# ATtiny841 device description
Architecture: AVR8; Family: tinyAVR
Registers are 8-bit, access not given, no defined reset value unless marked. A register's access mark holds for its fields unless they carry their own. Offsets are from the block's base; [hi:lo] are bit positions.

## PORTA — I/O Port
Instances: PORTA 0x00
0x39 PINA — Port A Input Pins
0x3A DDRA — Data Direction Register, Port A
0x3B PORTA — Port A Data Register
0x63 PUEA — Pull-up Enable Control Register
0x64 PORTCR — Port Control Register
  [0] BBMA — Break-Before-Make Mode Enable
0x6A PHDE — Port High Drive Enable Register
  [1:0] PHDEA — PortA High Drive Enable

## USART1 — USART
Instances: USART1 0x00
0x90 UDR1 — USART I/O Data Register
0x91 UBRR1 16-bit bits used 11:0 — USART Baud Rate Register Bytes
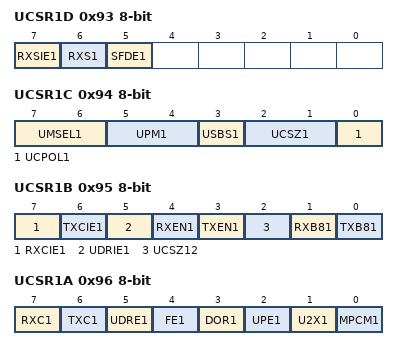
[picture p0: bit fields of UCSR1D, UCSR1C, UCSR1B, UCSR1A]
0x93 UCSR1D — USART Control and Status Register D
  [7] RXSIE1 — USART RX Start Interrupt Enable
  [6] RXS1 — USART RX Start Flag
  [5] SFDE1 — USART RX Start Frame Detection Enable
0x94 UCSR1C — USART Control and Status Register C
  [7:6] UMSEL1 — USART Mode Select
    0=Asynchronous USART; 1=Synchronous USART; 3=Master SPI
  [5:4] UPM1 — Parity Mode Bits
    0=Disabled; 2=Enabled, Even Parity; 3=Enabled, Odd Parity
  [3] USBS1 — Stop Bit Select
    0=1-bit; 1=2-bit
  [2:1] UCSZ1 — Character Size
  [0] UCPOL1 — Clock Polarity
0x95 UCSR1B — USART Control and Status Register B
  [7] RXCIE1 — RX Complete Interrupt Enable
  [6] TXCIE1 — TX Complete Interrupt Enable
  [5] UDRIE1 — USART Data register Empty Interrupt Enable
  [4] RXEN1 — Receiver Enable
  [3] TXEN1 — Transmitter Enable
  [2] UCSZ12 — Character Size
  [1] RXB81 — Receive Data Bit 8
  [0] TXB81 — Transmit Data Bit 8
0x96 UCSR1A — USART Control and Status Register A
  [7] RXC1 — USART Receive Complete
  [6] TXC1 — USART Transmitt Complete
  [5] UDRE1 — USART Data Register Empty
  [4] FE1 — Framing Error
  [3] DOR1 — Data overRun
  [2] UPE1 — Parity Error
  [1] U2X1 — Double the USART transmission speed
  [0] MPCM1 — Multi-processor Communication Mode

## USART0 — USART
Instances: USART0 0x00
0x65 REMAP — Remap Port Pins
  [0] U0MAP — USART0 Pin Mapping
0x80 UDR0 — USART I/O Data Register
0x81 UBRR0 16-bit bits used 11:0 — USART Baud Rate Register Bytes
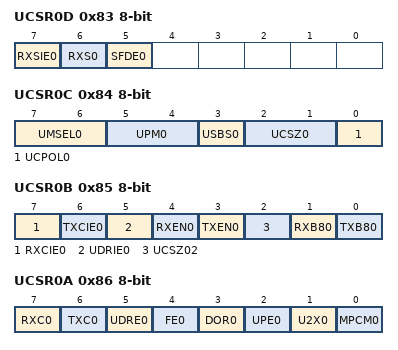
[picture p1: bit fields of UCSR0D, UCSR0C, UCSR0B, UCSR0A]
0x83 UCSR0D — USART Control and Status Register D
  [7] RXSIE0 — USART RX Start Interrupt Enable
  [6] RXS0 — USART RX Start Flag
  [5] SFDE0 — USART RX Start Frame Detection Enable
0x84 UCSR0C — USART Control and Status Register C
  [7:6] UMSEL0 — USART Mode Select
    0=Asynchronous USART; 1=Synchronous USART; 3=Master SPI
  [5:4] UPM0 — Parity Mode Bits
    0=Disabled; 2=Enabled, Even Parity; 3=Enabled, Odd Parity
  [3] USBS0 — Stop Bit Select
    0=1-bit; 1=2-bit
  [2:1] UCSZ0 — Character Size
  [0] UCPOL0 — Clock Polarity
0x85 UCSR0B — USART Control and Status Register B
  [7] RXCIE0 — RX Complete Interrupt Enable
  [6] TXCIE0 — TX Complete Interrupt Enable
  [5] UDRIE0 — USART Data register Empty Interrupt Enable
  [4] RXEN0 — Receiver Enable
  [3] TXEN0 — Transmitter Enable
  [2] UCSZ02 — Character Size
  [1] RXB80 — Receive Data Bit 8
  [0] TXB80 — Transmit Data Bit 8
0x86 UCSR0A — USART Control and Status Register A
  [7] RXC0 — USART Receive Complete
  [6] TXC0 — USART Transmitt Complete
  [5] UDRE0 — USART Data Register Empty
  [4] FE0 — Framing Error
  [3] DOR0 — Data overRun
  [2] UPE0 — Parity Error
  [1] U2X0 — Double the USART transmission speed
  [0] MPCM0 — Multi-processor Communication Mode

## WDT — Watchdog Timer
Instances: WDT 0x00
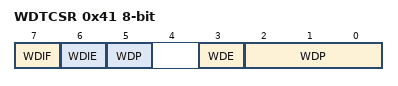
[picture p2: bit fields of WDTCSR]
0x41 WDTCSR — Watchdog Timer Control and Status Register
  [7] WDIF — Watchdog Timer Interrupt Flag
  [6] WDIE — Watchdog Timer Interrupt Enable
  [3] WDE — Watch Dog Enable
  [5,2:0] WDP — Watchdog Timer Prescaler Bits
    0=Oscillator Cycles 512 (16 ms); 1=Oscillator Cycles 1K (32 ms); 2=Oscillator Cycles 2K (64 ms); 3=Oscillator Cycles 4K (0.125 s); 4=Oscillator Cycles 8K (0.25 s); 5=Oscillator Cycles 16K (0.5 s); 6=Oscillator Cycles 32K (1.0 s); 7=Oscillator Cycles 64K (2.0 s); 8=Oscillator Cycles 128K (4.0 s); 9=Oscillator Cycles 256K (8.0 s)
